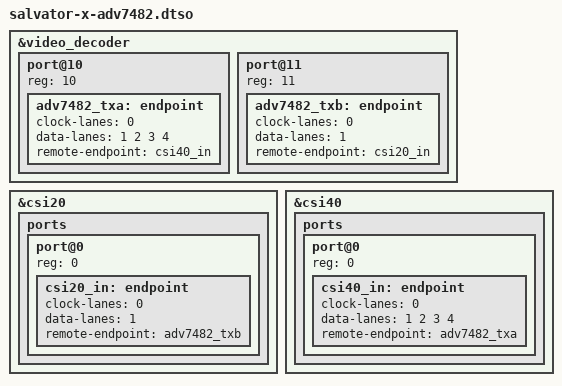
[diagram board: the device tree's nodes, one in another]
/*
 * Device Tree Source for ds90ux9xx_mipi as an overlay for the CLEO board
 *
 * Copyright (C) 2018 Robert Bosch Car Multimedia GmbH
 *
 * This file is licensed under the terms of the GNU General Public License
 * version 2.  This program is licensed "as is" without any warranty of any
 * kind, whether express or implied.
 */

/dts-v1/;
/plugin/;

&video_decoder {
	status = "okay";

	#address-cells = <1>;
	#size-cells = <0>;

	port@10 {
		reg = <10>;
		adv7482_txa: endpoint {
			clock-lanes = <0>;
			data-lanes = <1 2 3 4>;
			remote-endpoint = <&csi40_in>;
		};
	};

	port@11 {
		reg = <11>;
		adv7482_txb: endpoint {
			clock-lanes = <0>;
			data-lanes = <1>;
			remote-endpoint = <&csi20_in>;
		};
	};
};

&csi20 {
	ports {
		#address-cells = <1>;
		#size-cells = <0>;

		port@0 {
			reg = <0>;
			csi20_in: endpoint {
				clock-lanes = <0>;
				data-lanes = <1>;
				remote-endpoint = <&adv7482_txb>;
			};
		};
	};
};

&csi40 {
	ports {
		#address-cells = <1>;
		#size-cells = <0>;

		port@0 {
			reg = <0>;
			csi40_in: endpoint {
				clock-lanes = <0>;
				data-lanes = <1 2 3 4>;
				remote-endpoint = <&adv7482_txa>;
			};
		};
	};
};
